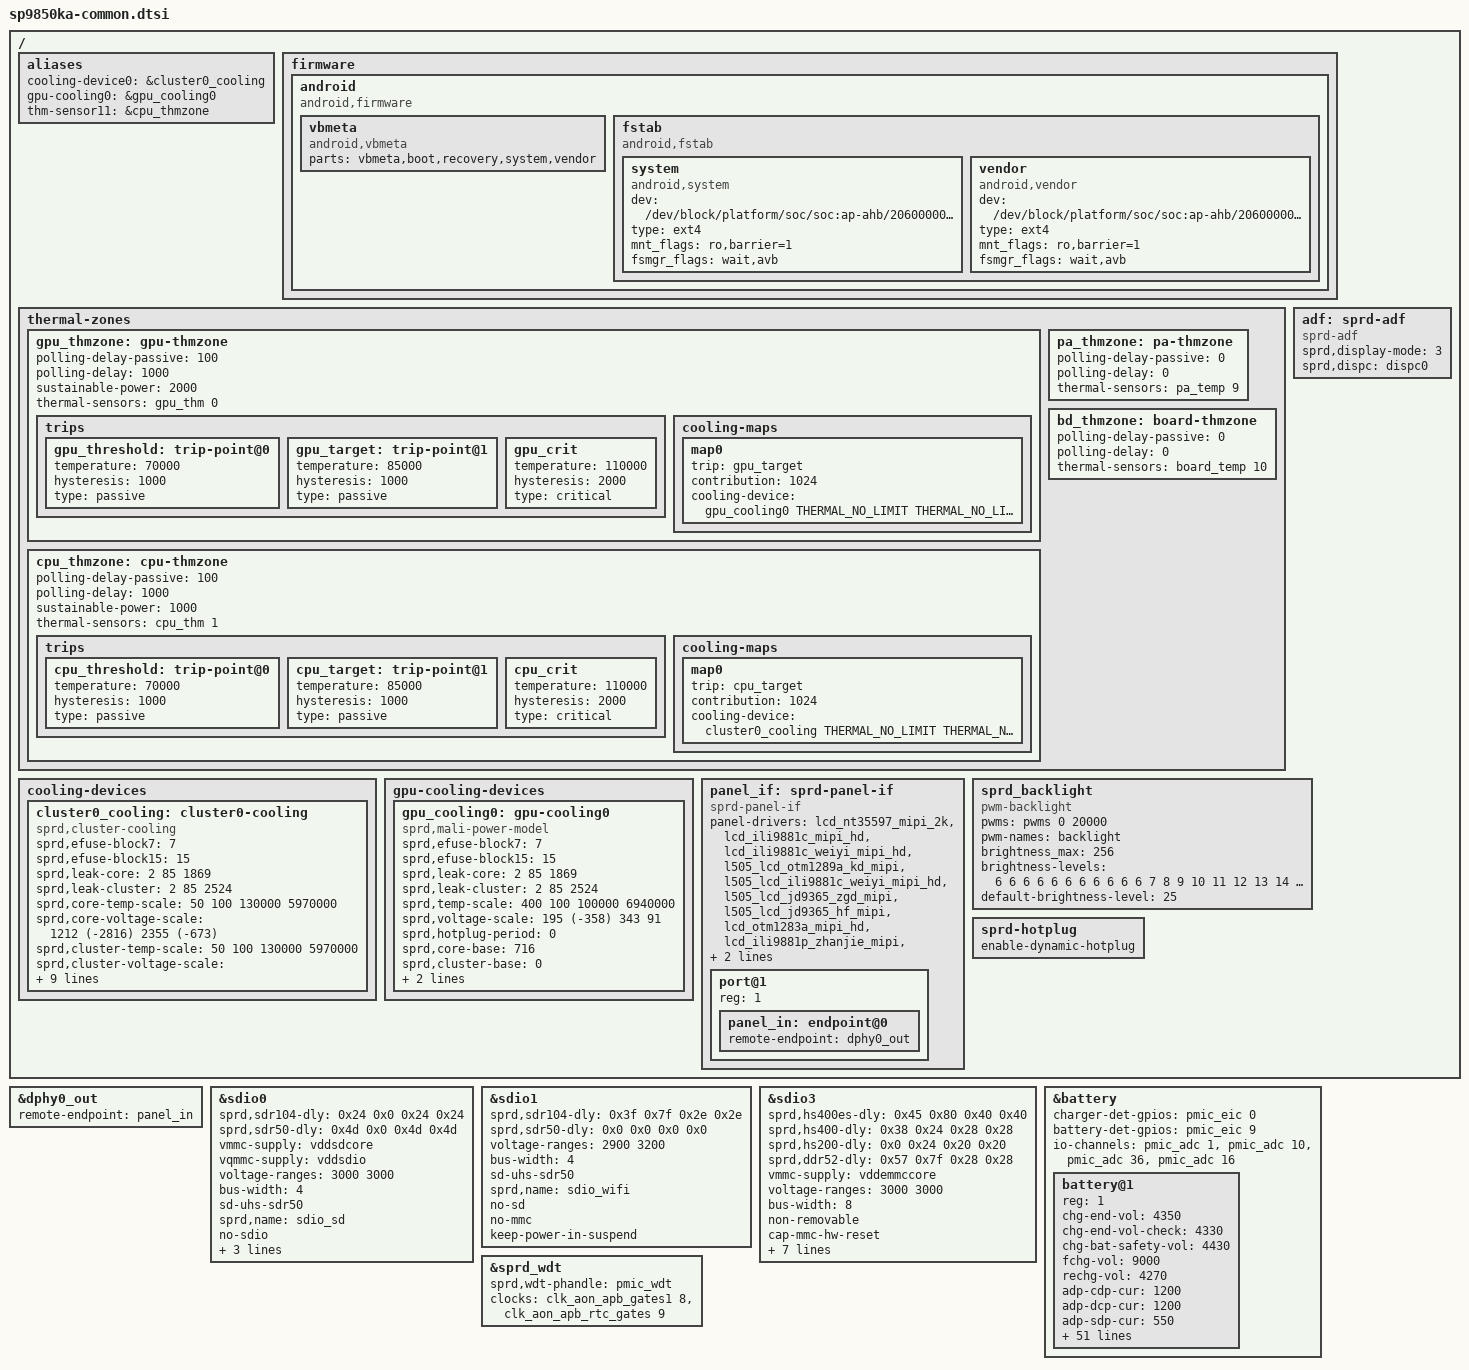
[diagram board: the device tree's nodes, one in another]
/*
 * Spreadtrum SP98x0 board common DTS file
 *
 * Copyright (C) 2016, Spreadtrum Communications Inc.
 *
 * This file is licensed under a dual GPLv2 or X11 license.
 */

#include "lcd/lcd_nt35597_mipi_2k.dtsi"
#include "lcd/lcd_ili9881c_mipi_hd.dtsi"
#include "lcd/lcd_ili9881c_weiyi_mipi_hd.dtsi"
#include "lcd/l505_lcd_ili9881c_weiyi_mipi_hd.dtsi"
#include "lcd/l505_lcd_jd9365_zgd_mipi.dtsi"
#include "lcd/l505_lcd_jd9365_hf_mipi.dtsi"
#include "lcd/l505_lcd_otm1289a_kd_mipi.dtsi"
#include "lcd/lcd_otm1283a_mipi_hd.dtsi"
#include "lcd/lcd_dummy_mipi.dtsi"
#include "lcd/lcd_ili9881p_zhanjie_mipi.dtsi"
#include "lcd/lcd_ft8006m_haifei_mipi_hd.dtsi"
#include "sc9850ka-modem.dtsi"
#include "sc2721.dtsi"
#include "sprd-battery.dtsi"
#include <dt-bindings/thermal/thermal.h>

/ {
	aliases {
		cooling-device0 = &cluster0_cooling;
		gpu-cooling0 = &gpu_cooling0;
		thm-sensor11 = &cpu_thmzone;
	};

	firmware {
		android {
			compatible = "android,firmware";

			vbmeta {
				compatible = "android,vbmeta";
				parts = "vbmeta,boot,recovery,system,vendor";
			};
			fstab {
				compatible = "android,fstab";
				system {
					compatible = "android,system";
					dev = "/dev/block/platform/soc/soc:ap-ahb/20600000.sdio/by-name/system";
					type = "ext4";
					mnt_flags = "ro,barrier=1";
					fsmgr_flags = "wait,avb";
				};
				vendor {
					compatible = "android,vendor";
					dev = "/dev/block/platform/soc/soc:ap-ahb/20600000.sdio/by-name/vendor";
					type = "ext4";
					mnt_flags = "ro,barrier=1";
					fsmgr_flags = "wait,avb";
				};
			};
		};
	};

	thermal-zones {

		gpu_thmzone: gpu-thmzone {
			polling-delay-passive = <100>;
			polling-delay = <1000>;
			sustainable-power = <2000>;
			thermal-sensors = <&gpu_thm  0>;
			trips {
				gpu_threshold: trip-point@0 {
					temperature = <70000>;
					hysteresis = <1000>;
					type = "passive";
				};
				gpu_target: trip-point@1 {
					temperature = <85000>;
					hysteresis = <1000>;
					type = "passive";
				};
				gpu_crit: gpu_crit {
					temperature = <110000>;
					hysteresis = <2000>;
					type = "critical";
				};
			};

			cooling-maps {
				map0 {
					trip = <&gpu_target>;
					contribution = <1024>;
					cooling-device =
					<&gpu_cooling0
						THERMAL_NO_LIMIT
						THERMAL_NO_LIMIT>;
				};
			};
		};

		cpu_thmzone: cpu-thmzone {
			polling-delay-passive = <100>;
			polling-delay = <1000>;
			sustainable-power = <1000>;
			thermal-sensors = <&cpu_thm  1>;
			trips {
				cpu_threshold: trip-point@0 {
					temperature = <70000>;
					hysteresis = <1000>;
					type = "passive";
				};
				cpu_target: trip-point@1 {
					temperature = <85000>;
					hysteresis = <1000>;
					type = "passive";
				};
				cpu_crit: cpu_crit {
					temperature = <110000>;
					hysteresis = <2000>;
					type = "critical";
				};
			};

			cooling-maps {
				map0 {
					trip = <&cpu_target>;
					contribution = <1024>;
					cooling-device =
					<&cluster0_cooling
						THERMAL_NO_LIMIT
						THERMAL_NO_LIMIT>;
				};
			};
		};

		pa_thmzone: pa-thmzone {
			polling-delay-passive = <0>;
			polling-delay = <0>;
			thermal-sensors = <&pa_temp  9>;
		};

		bd_thmzone: board-thmzone {
			polling-delay-passive = <0>;
			polling-delay = <0>;
			thermal-sensors = <&board_temp  10>;
		};
	};

	cooling-devices {
		cluster0_cooling: cluster0-cooling {
			compatible = "sprd,cluster-cooling";
			#cooling-cells = <2>; /* min followed by max */
			sprd,efuse-block7 = <7>;
			sprd,efuse-block15 = <15>;
			/* core_leak =                             */
			/*(LIT_LEAK[4:0]+1) x 2mA x 0.85V x 18.69% */
			sprd,leak-core = <2 85 1869>;
			/* cluster_leak =                           */
			/* (LIT_LEAK[4:0]+1) x 2mA x 0.85V x 25.24% */
			sprd,leak-cluster = <2 85 2524>;
			/*core Tscale = aT^3 + bT^2 + cT +di   */
			sprd,core-temp-scale =
			/* a*10^7   b*10^7      c*10^7     d*10^7 */
			<  50       100         130000     5970000>;
			/*core Vscale = eV^3 + fV^2 + gV + h */
			sprd,core-voltage-scale =
			/* e*10^2   f*10^2     g*10^2  h*10^2*/
			<  1212     (-2816)    2355    (-673)>;
			/*cluster Tscale = aT^3 + bT^2 + cT +di   */
			sprd,cluster-temp-scale =
			/* a*10^7   b*10^7      c*10^7     d*10^7 */
			<  50       100         130000     5970000>;
			/*cluster Vscale = eV^3 + fV^2 + gV + h */
			sprd,cluster-voltage-scale =
			/* e*10^2   f*10^2     g*10^2  h*10^2*/
			<  1212     (-2816)    2355    (-673)>;
			sprd,efuse-switch = <0>;
			sprd,hotplug-period = <10>;
			sprd,min-cpufreq = <768000>;
			sprd,min-cpunum = <4>;
			sprd,core-base = <327>;
			sprd,cluster-base = <599>;
			sprd,dynamic-core =
			/*Pdynperghz    Freq     Vbase  */
			< 1240          768      1050>;
			sprd,dynamic-cluster =
			/*Pdynperghz    Freq     Vbase  */
			< 348           768      1050>;
		};
	};

	gpu-cooling-devices {
		gpu_cooling0: gpu-cooling0 {
			compatible = "sprd,mali-power-model";
			#cooling-cells = <2>;
			sprd,efuse-block7 = <7>;
			sprd,efuse-block15 = <15>;
			/* core_leak =                             */
			/*(LIT_LEAK[4:0]+1) x 2mA x 0.85V x 18.69% */
			sprd,leak-core = <2 85 1869>;
			/* cluster_leak =                           */
			/* (LIT_LEAK[4:0]+1) x 2mA x 0.85V x 25.24% */
			sprd,leak-cluster = <2 85 2524>;
			/*Tscale = aT^3 + bT^2 + cT +di   */
			sprd,temp-scale =
			/* a*10^7   b*10^7      c*10^7     d*10^7 */
			<  400      100        100000    6940000>;
			/*Vscale = eV^3 + fV^2 + gV + h */
			sprd,voltage-scale =
			/* e*10^2   f*10^2     g*10^2  h*10^2*/
			<  195      (-358)     343     91>;
			sprd,hotplug-period = <0>;
			sprd,core-base = <716>;
			sprd,cluster-base = <0>;
			sprd,dynamic-core =
			/*Pdynperghz    Freq     Vbase  */
			< 9230           768     1050>;
			sprd,dynamic-cluster =
			/*Pdynperghz    Freq     Vbase  */
			< 0              0       0>;
		};
	};

	panel_if: sprd-panel-if {
		compatible = "sprd-panel-if";
		#address-cells = <1>;
		#size-cells = <0>;
		panel-drivers = <
			&lcd_nt35597_mipi_2k
			&lcd_ili9881c_mipi_hd
			&lcd_ili9881c_weiyi_mipi_hd
			&l505_lcd_otm1289a_kd_mipi
			&l505_lcd_ili9881c_weiyi_mipi_hd
			&l505_lcd_jd9365_zgd_mipi
			&l505_lcd_jd9365_hf_mipi
			&lcd_otm1283a_mipi_hd
			&lcd_ili9881p_zhanjie_mipi
			&lcd_ft8006m_haifei_mipi_hd
			&lcd_dummy_mipi_hd
		>;

		/* input port */
		port@1 {
		/* WARNING: the reg property must be 1 ! */
			reg = <1>;
			panel_in: endpoint@0 {
				remote-endpoint = <&dphy0_out>;
			};
		};
	};

	adf: sprd-adf {
		compatible = "sprd-adf";
		status = "okay";
		sprd,display-mode = <3>;
		sprd,dispc = <&dispc0>;
	};

	sprd_backlight {
		compatible = "pwm-backlight";
		pwms = <&pwms 0 20000>;
		pwm-names = "backlight";
		brightness_max = <256>;
		brightness-levels=<
						  6   6   6   6
			  6   6   6   6   6   6   6   7   8   9
			 10  11  12  13  14  15  16  17  18  19
			 20  21  22  23  24  25  26  27  28  29
			 30  31  32  33  34  35  36  37  38  39
			 40  41  42  43  44  45  46  47  48  49
			 50  51  52  53  54  55  56  57  58  59
			 60  61  62  63  64  65  66  67  68  69
			 70  71  72  73  74  75  76  77  78  79
			 80  81  82  83  84  85  86  87  88  89
			 90  91  92  93  94  95  96  97  98  99
			100 101 102 103 104 105 106 107 108 109
			110 111 112 113 114 115 116 117 118 119
			120 121 122 123 124 125 126 127 128 129
			130 131 132 133 134 135 136 137 138 139
			140 141 142 143 144 145 146 147 148 149
			150 151 152 153 154 155 156 157 158 159
			160 161 162 163 164 165 166 167 168 169
			170 171 172 173 174 175 176 177 178 179
			180 181 182 183 184 185 186 187 188 189
			190 191 192 193 194 195 196 197 198 199
			200 201 202 203 204 205 206 207 208 209
			210 211 212 213 214 215 216 217 218 219
			220 221 222 223 224 225 226 227 228 229
			230 231 232 233 234 235 236 237 238 239
			240 241 242 243 244 245 246 247 248 249
			250 251
			>;
		default-brightness-level = <25>;
	};

	sprd-hotplug {
		enable-dynamic-hotplug;
	};
};

&dphy0_out {
	remote-endpoint = <&panel_in>;
};

&sdio0 {
	sprd,sdr104-dly = <0x24 0x0 0x24 0x24>;
	sprd,sdr50-dly = <0x4d 0x0 0x4d 0x4d>;
	vmmc-supply = <&vddsdcore>;
	vqmmc-supply = <&vddsdio>;
	voltage-ranges = <3000 3000>;
	bus-width = <4>;
	sd-uhs-sdr50;
	sprd,name = "sdio_sd";
	no-sdio;
	no-mmc;
	pinctrl-names = "sd0_ms_0","sd0_ms_1";
	pinctrl-0 = <&vio_sd0_ms_0>;
	pinctrl-1 = <&vio_sd0_ms_1>;
	status = "okay";
};

&sdio1 {
	sprd,sdr104-dly = <0x3f 0x7f 0x2e 0x2e>;
	sprd,sdr50-dly = <0x0 0x0 0x0 0x0>;
	voltage-ranges = <2900 3200>;
	bus-width = <4>;
	sd-uhs-sdr50;
	sprd,name = "sdio_wifi";
	no-sd;
	no-mmc;
	keep-power-in-suspend;
	status = "okay";
};

&sdio3 {
	sprd,hs400es-dly = <0x45 0x80 0x40 0x40>;
	sprd,hs400-dly = <0x38 0x24 0x28 0x28>;
	sprd,hs200-dly = <0x0 0x24 0x20 0x20>;
	sprd,ddr52-dly = <0x57 0x7f 0x28 0x28>;
	vmmc-supply = <&vddemmccore>;
	voltage-ranges = <3000 3000>;
	bus-width = <8>;
	non-removable;
	cap-mmc-hw-reset;
	mmc-hs400-enhanced-strobe;
	mmc-hs400-1_8v;
	mmc-hs200-1_8v;
	mmc-ddr-1_8v;
	sprd,name = "sdio_emmc";
	no-sdio;
	no-sd;
	status = "okay";
};

&battery {
	#address-cells = <1>;
	#size-cells = <0>;
	charger-det-gpios = <&pmic_eic 0 0>;
	battery-det-gpios = <&pmic_eic 9 0>;
	io-channels = <&pmic_adc 1>,<&pmic_adc 10>,
			<&pmic_adc 36>,<&pmic_adc 16>;
	io-channel-names = "adc_temp","adc_vbat",
			"adc_vchg","adc_isense";
	status = "okay";
	battery@1 {
		reg = <1>;
		chg-end-vol = <4350>;
		chg-end-vol-check = <4330>;
		chg-bat-safety-vol = <4430>;
		fchg-vol = <9000>;
		rechg-vol = <4270>;
		adp-cdp-cur = <1200>;
		adp-dcp-cur = <1200>;
		adp-sdp-cur = <550>;
		adp-unknown-cur = <550>;
		adp-fchg-cur = <3000>;
		adp-cdp-cur-limit = <1500>;
		adp-dcp-cur-limit = <3000>;
		adp-sdp-cur-limit = <500>;
		adp-fchg-cur-limit = <2000>;
		adp-unknown-cur-limit = <500>;
		ovp-stop = <6500>;
		ovp-restart = <5800>;
		fchg-ovp-stop = <11000>;
		fchg-ovp-restart = <10000>;
		chg-timeout = <21600>;
		chg-rechg-timeout = <5400>;
		chg-end-cur = <111>;
		chg-polling-time = <15>;
		chg-polling-time-fast = <1>;
		cap-one-per-time = <30>;
		/*0 vol and cur,1 status and cur,2 ext ic*/
		chg-full-condition = <0>;
		temp-support = <0>;
		/*30mohm,if temp-table-mode = <1>, use it*/
		temp-comp-res = <6>;
		temp-tab-val = <1052 953 858 762 671 584
				504 434 372 318 271 234
				198 165 140 119 104 88>;
		/* temperature + 1000,750 = 1000 + (-250)*/
		temp-tab-temp = <750 800 850 900 950 1000
				 1050 1100 1150 1200 1250 1300
				 1350 1400 1450 1500 1550 1600>;
		jeita-temp-tab = <900 1000 1100 1450 1500>;
		jeita-temp-recovery-tab = <930 1030 1130 1420 1470>;
		jeita-cur-tab = <0 100 500 0x7FFF 700 0>;
		jeita-cccv-tab = <4200 4200 4350 4350 4350 4350>;
		fgu-mode = <0>;
		alm-soc = <5>;
		alm-vol = <3450>;
		soft-vbat-uvlo = <3050>;
		rint = <250>;
		cnom = <2500>;
		rsense-real = <200>;
		rsense-spec = <200>;
		relax-current = <50>;
		fgu-cal-ajust = <0>;
		ocv-tab-vol = <4340 4216 4154 4102 4055 4011 3971
				3935 3903 3865 3827 3802 3786 3776
				3771 3767 3757 3732 3683 3605 3400>;
		ocv-tab-cap = <100  95   90   85   80   75   70
				65   60   55   50   45   40   35
				 30   25   20   15   10   5    0>;
		cnom-temp-tab = <1020 1800	/*value = 1000 + temp*/
				1010 1300
				1000 1070
				990  1000>;
		rint-temp-tab = <1020 200	/*value = 1000 + temp*/
				1010 450
				1000 650
				990  1100>;
		charger-det-gpios = <&pmic_eic 0 0>;
		battery-det-gpios = <&pmic_eic 9 0>;
		io-channels = <&pmic_adc 1>,<&pmic_adc 10>,
				<&pmic_adc 36>,<&pmic_adc 16>;
		io-channel-names = "adc_temp","adc_vbat",
				"adc_vchg","adc_isense";
	};
};

&sprd_wdt {
	sprd,wdt-phandle = <&pmic_wdt>;
	clocks = <&clk_aon_apb_gates1 8>, <&clk_aon_apb_rtc_gates 9>;
};
